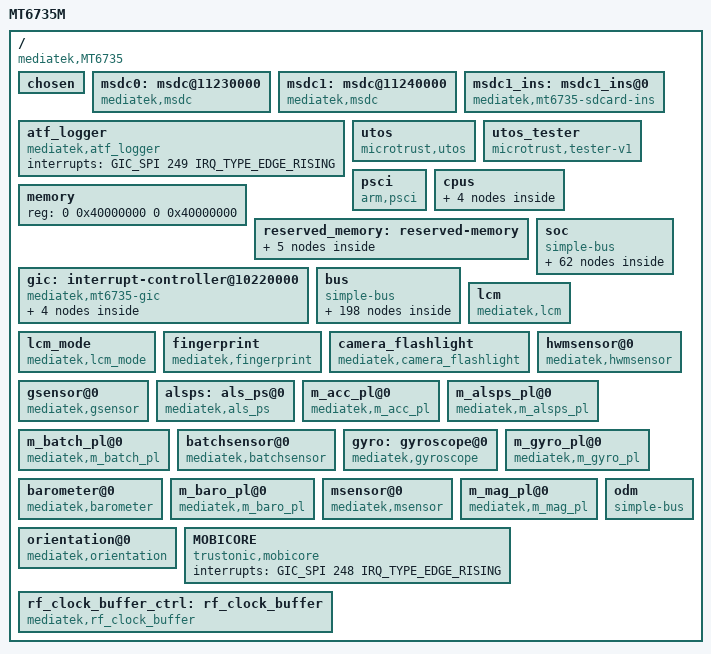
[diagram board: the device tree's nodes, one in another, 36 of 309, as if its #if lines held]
/*
 * Copyright (c) 2015 MediaTek Inc.
 *
 * This program is free software; you can redistribute it and/or modify
 * it under the terms of the GNU General Public License version 2 as
 * published by the Free Software Foundation.
 *
 * This program is distributed in the hope that it will be useful,
 * but WITHOUT ANY WARRANTY; without even the implied warranty of
 * MERCHANTABILITY or FITNESS FOR A PARTICULAR PURPOSE.  See the
 * GNU General Public License for more details.
 */

#include <dt-bindings/interrupt-controller/arm-gic.h>
#include <dt-bindings/interrupt-controller/irq.h>
#include "mt6735m-pinfunc.h"
#include <dt-bindings/mmc/mt6735-msdc.h>
#include <generated/autoconf.h>

#ifdef CONFIG_MTK_DTBO_FEATURE
/dts-v1/;
#endif

/ {
	model = "MT6735M";
	compatible = "mediatek,MT6735";
	interrupt-parent = <&gic>;
	#address-cells = <2>;
	#size-cells = <2>;

	/* chosen */
	chosen: chosen {
		bootargs = "console=tty0 console=ttyMT3,921600n1 vmalloc=400M \
androidboot.hardware=mt6735 slub_max_order=0 slub_debug=OFZPU swiotlb=noforce \
firmware_class.path=/vendor/firmware loop.max_part=7";
	};

	msdc0:msdc@11230000 {
		compatible = "mediatek,msdc";
		reg = <0 0x11230000 0 0x10000>;
		interrupts = <GIC_SPI 79 IRQ_TYPE_LEVEL_LOW>;
	};

	msdc1:msdc@11240000 {
		compatible = "mediatek,msdc";
		reg = <0 0x11240000 0 0x10000>;
		interrupts = <GIC_SPI 80 IRQ_TYPE_LEVEL_LOW>;
	};

	msdc1_ins:msdc1_ins@0 {
		compatible = "mediatek,mt6735-sdcard-ins";
	};

	/* ATF logger SW IRQ number 281 = 32 + 249 */
	atf_logger {
		compatible = "mediatek,atf_logger";
		interrupts = <GIC_SPI 249 IRQ_TYPE_EDGE_RISING>;
	};

	utos {
	compatible = "microtrust,utos";
	interrupts = <GIC_SPI 252 IRQ_TYPE_EDGE_RISING>,
		<GIC_SPI 253 IRQ_TYPE_EDGE_RISING>;
	};
	utos_tester {
		compatible = "microtrust,tester-v1";
	};

	psci {
		compatible	= "arm,psci";
		method		= "smc";
		cpu_suspend	= <0x84000001>;
		cpu_off		= <0x84000002>;
		cpu_on		= <0x84000003>;
		affinity_info	= <0x84000004>;
	};

	cpus: cpus {
		#address-cells = <1>;
		#size-cells = <0>;
/*		enable-method = "mediatek,mt6735-smp"; */

		cpu0: cpu@000 {
			device_type = "cpu";
			compatible = "arm,cortex-a53";
			reg = <0x000>;
			enable-method = "spin-table";
			cpu-release-addr = <0x0 0x40000200>;
			clock-frequency = <1000000000>;
		};

		cpu1: cpu@001 {
			device_type = "cpu";
			compatible = "arm,cortex-a53";
			reg = <0x001>;
			enable-method = "spin-table";
			cpu-release-addr = <0x0 0x40000200>;
			clock-frequency = <1000000000>;
		};

		cpu2: cpu@002 {
			device_type = "cpu";
			compatible = "arm,cortex-a53";
			reg = <0x002>;
			enable-method = "spin-table";
			cpu-release-addr = <0x0 0x40000200>;
			clock-frequency = <1000000000>;
		};

		cpu3: cpu@003 {
			device_type = "cpu";
			compatible = "arm,cortex-a53";
			reg = <0x003>;
			enable-method = "spin-table";
			cpu-release-addr = <0x0 0x40000200>;
			clock-frequency = <1000000000>;
		};
	};

	memory {
		device_type = "memory";
		reg = <0 0x40000000 0 0x40000000>;
	};


		reserved_memory: reserved-memory {
				#address-cells = <2>;
				#size-cells = <2>;
				ranges;

				/* reserve 192KB at DRAM start + 48MB */
				atf-reserved-memory@43000000 {
						compatible = "mediatek,mt6735-atf-reserved-memory",
						"mediatek,mt6735m-atf-reserved-memory",
						"mediatek,mt6753-atf-reserved-memory";
						no-map;
						reg = <0 0x43000000 0 0x30000>;
				};

		reserve-memory-ccci_md1 {
						compatible = "mediatek,reserve-memory-ccci_md1";
						no-map;
						size = <0 0x3810000>; // md_size+smem_size
						alignment = <0 0x2000000>;
						alloc-ranges = <0 0x40000000 0 0xC0000000>;
				};

				consys-reserve-memory {
						compatible = "mediatek,consys-reserve-memory";
						no-map;
						size = <0 0x100000>;
						alignment = <0 0x200000>;
				};

#ifdef CONFIG_MICROTRUST_TEE_SUPPORT
		soter-shared-mem {
			compatible = "microtrust,shared_mem";
			no-map;
			size = <0 0x200000>;
			alloc-ranges = <0 0x40000000 0 0x50000000>;
		};
#endif

				spm-reserve-memory {
					compatible = "mediatek,spm-reserve-memory";
					no-map;
					size = <0 0x10000>; /* PCM_FIRMWARE_SIZE * DYNA_LOAD_PCM_MAX = 4K * 4 */
					alignment = <0 0x10000>;
					alloc-ranges = <0 0x40000000 0 0x60000000>;
				};
		};

		gic: interrupt-controller@10220000 {
				compatible = "mediatek,mt6735-gic";
				#interrupt-cells = <3>;
				#address-cells = <0>;
				interrupt-controller;
				reg = <0 0x10221000 0 0x1000>,
					<0 0x10222000 0 0x1000>,
					<0 0x10200620 0 0x1000>;

				mediatek,wdt_irq = <160>;

				gic-cpuif@0 {
					compatible = "arm,gic-cpuif";
					cpuif-id = <0>;
					cpu = <&cpu0>;
				};

				gic-cpuif@1 {
					compatible = "arm,gic-cpuif";
					cpuif-id = <1>;
					cpu = <&cpu1>;
				};

				gic-cpuif@2 {
					compatible = "arm,gic-cpuif";
					cpuif-id = <2>;
					cpu = <&cpu2>;
				};

				gic-cpuif@3 {
					compatible = "arm,gic-cpuif";
					cpuif-id = <3>;
					cpu = <&cpu3>;
				};

		};

	soc {
		compatible = "simple-bus";
		#address-cells = <1>;
		#size-cells = <1>;
		ranges = <0 0 0 0xffffffff>;

		cpuxgpt: cpuxgpt@10200000 {
			compatible = "mediatek,mt6735-cpuxgpt";
			reg = <0x10200000 0x1000>;
			interrupts = <GIC_SPI 64 IRQ_TYPE_LEVEL_HIGH>,
				<GIC_SPI 65 IRQ_TYPE_LEVEL_HIGH>,
				<GIC_SPI 66 IRQ_TYPE_LEVEL_HIGH>,
				<GIC_SPI 67 IRQ_TYPE_LEVEL_HIGH>,
				<GIC_SPI 68 IRQ_TYPE_LEVEL_HIGH>,
				<GIC_SPI 69 IRQ_TYPE_LEVEL_HIGH>,
				<GIC_SPI 70 IRQ_TYPE_LEVEL_HIGH>,
				<GIC_SPI 71 IRQ_TYPE_LEVEL_HIGH>;
		};

		apxgpt: apxgpt@10004000 {
			compatible = "mediatek,APXGPT";
			reg = <0x10004000 0x1000>;
			interrupts = <GIC_SPI 152 IRQ_TYPE_LEVEL_LOW>;
			clock-frequency = <13000000>;
		};

		pmu {
			compatible = "arm,cortex-a7-pmu";
			interrupts = <GIC_SPI 8 IRQ_TYPE_LEVEL_LOW>,
				<GIC_SPI 9 IRQ_TYPE_LEVEL_LOW>,
				<GIC_SPI 10 IRQ_TYPE_LEVEL_LOW>,
				<GIC_SPI 11 IRQ_TYPE_LEVEL_LOW>;
			interrupt-affinity = <&cpu0>,
					     <&cpu1>,
					     <&cpu2>,
					     <&cpu3>;
		};

		timer {
			compatible = "arm,armv8-timer";
			interrupts = <GIC_PPI 13 IRQ_TYPE_LEVEL_LOW>, /*Secure Physical Timer Event*/
				<GIC_PPI 14 IRQ_TYPE_LEVEL_LOW>, /*Non-Secure Physical Timer Event*/
				<GIC_PPI 11 IRQ_TYPE_LEVEL_LOW>, /*Virtual Timer Event*/
				<GIC_PPI 10 IRQ_TYPE_LEVEL_LOW>; /*Hypervisor Timer Event*/
				clock-frequency = <13000000>;
		};

		mt_pmic_regulator {
			compatible = "mediatek,mt_pmic";
			/*reg = <0x01>*/
			buck_regulators {
			compatible = "mediatek,mt_pmic_buck_regulators";
				mt_pmic_vpa_buck_reg: buck_vpa {
					regulator-name = "vpa";
					regulator-min-microvolt = <500000>;
					regulator-max-microvolt = <3650000>;
					regulator-ramp-delay = <50000>;
					regulator-enable-ramp-delay = <180>;
				};
				mt_pmic_vproc_buck_reg: buck_vproc {
					regulator-name = "vproc";
					regulator-min-microvolt = <600000>;
					regulator-max-microvolt = <1393750>;
					regulator-ramp-delay = <6250>;
					regulator-enable-ramp-delay = <180>;
					regulator-always-on;
					regulator-boot-on;
				};
				mt_pmic_vcore1_buck_reg: buck_vcore1 {
					regulator-name = "vcore1";
					regulator-min-microvolt = <600000>;
					regulator-max-microvolt = <1393750>;
					regulator-ramp-delay = <6250>;
					regulator-enable-ramp-delay = <180>;
					regulator-always-on;
					regulator-boot-on;
				};
				mt_pmic_vsys22_buck_reg: buck_vsys22 {
					regulator-name = "vsys22";
					regulator-min-microvolt = <1200000>;
					regulator-max-microvolt = <1993750>;
					regulator-ramp-delay = <6250>;
					regulator-enable-ramp-delay = <180>;
					regulator-always-on;
					regulator-boot-on;
				};
				mt_pmic_vlte_buck_reg: buck_vlte {
					regulator-name = "vlte";
					regulator-min-microvolt = <600000>;
					regulator-max-microvolt = <1393750>;
					regulator-ramp-delay = <6250>;
					regulator-enable-ramp-delay = <180>;
					regulator-always-on;
					regulator-boot-on;
				};
			};	/* End of buck_regulators */
			ldo_regulators {
				compatible = "mediatek,mt_pmic_ldo_regulators";
				mt_pmic_vaux18_ldo_reg: ldo_vaux18 {
					regulator-name = "vaux18";
					regulator-min-microvolt = <1800000>;
					regulator-max-microvolt = <1800000>;
					regulator-enable-ramp-delay = <264>;
					regulator-boot-on;
				};
				mt_pmic_vtcxo_0_ldo_reg: ldo_vtcxo_0 {
					regulator-name = "vtcxo_0";
					regulator-min-microvolt = <2800000>;
					regulator-max-microvolt = <2800000>;
					regulator-enable-ramp-delay = <110>;
					regulator-boot-on;
				};
				mt_pmic_vtcxo_1_ldo_reg: ldo_vtcxo_1 {
					regulator-name = "vtcxo_1";
					regulator-min-microvolt = <2800000>;
					regulator-max-microvolt = <2800000>;
					regulator-enable-ramp-delay = <110>;
				};
				mt_pmic_vaud28_ldo_reg: ldo_vaud28 {
					regulator-name = "vaud28";
					regulator-min-microvolt = <2800000>;
					regulator-max-microvolt = <2800000>;
					regulator-enable-ramp-delay = <264>;
					regulator-boot-on;
				};
				mt_pmic_vcn28_ldo_reg: ldo_vcn28 {
					regulator-name = "vcn28";
					regulator-min-microvolt = <2800000>;
					regulator-max-microvolt = <2800000>;
					regulator-enable-ramp-delay = <264>;
				};
				mt_pmic_vcama_ldo_reg: ldo_vcama {
					regulator-name = "vcama";
					regulator-min-microvolt = <1500000>;
					regulator-max-microvolt = <2800000>;
					regulator-enable-ramp-delay = <264>;
				};
				mt_pmic_vcn33_bt_ldo_reg: ldo_vcn33_bt {
					regulator-name = "vcn33_bt";
					regulator-min-microvolt = <3300000>;
					regulator-max-microvolt = <3600000>;
					regulator-enable-ramp-delay = <264>;
				};
				mt_pmic_vcn33_wifi_ldo_reg: ldo_vcn33_wifi {
					regulator-name = "vcn33_wifi";
					regulator-min-microvolt = <3300000>;
					regulator-max-microvolt = <3600000>;
					regulator-enable-ramp-delay = <264>;
				};
				mt_pmic_vusb33_ldo_reg: ldo_vusb33 {
					regulator-name = "vusb33";
					regulator-min-microvolt = <3300000>;
					regulator-max-microvolt = <3300000>;
					regulator-enable-ramp-delay = <264>;
					regulator-boot-on;
				};
				mt_pmic_vefuse_ldo_reg: ldo_vefuse {
					regulator-name = "vefuse";
					regulator-min-microvolt = <1800000>;
					regulator-max-microvolt = <2200000>;
					regulator-enable-ramp-delay = <264>;
				};
				mt_pmic_vsim1_ldo_reg: ldo_vsim1 {
					regulator-name = "vsim1";
					regulator-min-microvolt = <1700000>;
					regulator-max-microvolt = <2100000>;
					regulator-enable-ramp-delay = <264>;
				};
				mt_pmic_vsim2_ldo_reg: ldo_vsim2 {
					regulator-name = "vsim2";
					regulator-min-microvolt = <1700000>;
					regulator-max-microvolt = <2100000>;
					regulator-enable-ramp-delay = <264>;
				};
				mt_pmic_vemc33_ldo_reg: ldo_vemc_3v3 {
					regulator-name = "vemc_3v3";
					regulator-min-microvolt = <1800000>;
					regulator-max-microvolt = <3300000>;
					regulator-enable-ramp-delay = <264>;
					regulator-boot-on;
				};
				mt_pmic_vmch_ldo_reg: ldo_vmch {
					regulator-name = "vmch";
					regulator-min-microvolt = <2900000>;
					regulator-max-microvolt = <3300000>;
					regulator-enable-ramp-delay = <44>;
				};
				mt_pmic_vtref_ldo_reg: ldo_vtref {
					regulator-name = "vtref";
					regulator-min-microvolt = <1800000>;
					regulator-max-microvolt = <1800000>;
					regulator-enable-ramp-delay = <240>;
				};
				mt_pmic_vmc_ldo_reg: ldo_vmc {
					regulator-name = "vmc";
					regulator-min-microvolt = <1800000>;
					regulator-max-microvolt = <3300000>;
					regulator-enable-ramp-delay = <44>;
				};
				mt_pmic_vcam_af_ldo_reg: ldo_vcamaf {
					regulator-name = "vcamaf";
					regulator-min-microvolt = <1200000>;
					regulator-max-microvolt = <3300000>;
					regulator-enable-ramp-delay = <264>;
				};
				mt_pmic_vio28_ldo_reg: ldo_vio28 {
					regulator-name = "vio28";
					regulator-min-microvolt = <2800000>;
					regulator-max-microvolt = <2800000>;
					regulator-enable-ramp-delay = <264>;
					regulator-boot-on;
				};
				mt_pmic_vgp1_ldo_reg: ldo_vgp1 {
					regulator-name = "vgp1";
					regulator-min-microvolt = <1200000>;
					regulator-max-microvolt = <3300000>;
					regulator-enable-ramp-delay = <264>;
				};
				mt_pmic_vibr_ldo_reg: ldo_vibr {
					regulator-name = "vibr";
					regulator-min-microvolt = <1200000>;
					regulator-max-microvolt = <3300000>;
					regulator-enable-ramp-delay = <44>;
				};
				mt_pmic_vcamd_ldo_reg: ldo_vcamd {
					regulator-name = "vcamd";
					regulator-min-microvolt = <900000>;
					regulator-max-microvolt = <1500000>;
					regulator-enable-ramp-delay = <264>;
				};
				mt_pmic_vrf18_0_ldo_reg: ldo_vrf18_0 {
					regulator-name = "vrf18_0";
					regulator-min-microvolt = <1825000>;
					regulator-max-microvolt = <1825000>;
					regulator-enable-ramp-delay = <220>;
				};
				mt_pmic_vrf18_1_ldo_reg: ldo_vrf18_1 {
					regulator-name = "vrf18_1";
					regulator-min-microvolt = <1200000>;
					regulator-max-microvolt = <1825000>;
					regulator-enable-ramp-delay = <220>;
				};
				mt_pmic_vio18_ldo_reg: ldo_vio18 {
					regulator-name = "vio18";
					regulator-min-microvolt = <1800000>;
					regulator-max-microvolt = <1800000>;
					regulator-enable-ramp-delay = <264>;
					regulator-boot-on;
				};
				mt_pmic_vcn18_ldo_reg: ldo_vcn18 {
					regulator-name = "vcn18";
					regulator-min-microvolt = <1800000>;
					regulator-max-microvolt = <1800000>;
					regulator-enable-ramp-delay = <44>;
				};
				mt_pmic_vcam_io_ldo_reg: ldo_vcamio {
					regulator-name = "vcamio";
					regulator-min-microvolt = <1200000>;
					regulator-max-microvolt = <1800000>;
					regulator-enable-ramp-delay = <220>;
				};
				mt_pmic_vsram_ldo_reg: ldo_vsram {
					regulator-name = "vsram";
					regulator-min-microvolt = <700000>;
					regulator-max-microvolt = <1493750>;
					regulator-enable-ramp-delay = <220>;
					regulator-ramp-delay = <6250>;
					regulator-boot-on;
				};
				mt_pmic_vm_ldo_reg: ldo_vm {
					regulator-name = "vm";
					regulator-min-microvolt = <1240000>;
					regulator-max-microvolt = <1540000>;
					regulator-enable-ramp-delay = <264>;
					regulator-boot-on;
				};
			};/* End of ldo_regulators */
			regulators_supply {
				compatible = "mediatek,mt_pmic_regulator_supply";
				vaux18-supply = <&mt_pmic_vaux18_ldo_reg>;
				vtcxo_0-supply = <&mt_pmic_vtcxo_0_ldo_reg>;
				vtcxo_1-supply = <&mt_pmic_vtcxo_1_ldo_reg>;
				vaud28-supply = <&mt_pmic_vaud28_ldo_reg>;
				vefuse-supply = <&mt_pmic_vefuse_ldo_reg>;
				vsim1-supply = <&mt_pmic_vsim1_ldo_reg>;
				vsim2-supply = <&mt_pmic_vsim2_ldo_reg>;
				vemc_3v3-supply = <&mt_pmic_vemc33_ldo_reg>;
				vmch-supply = <&mt_pmic_vmch_ldo_reg>;
				vtref-supply = <&mt_pmic_vtref_ldo_reg>;
				vmc-supply = <&mt_pmic_vmc_ldo_reg>;
				vio28-supply = <&mt_pmic_vio28_ldo_reg>;
				vibr-supply = <&mt_pmic_vibr_ldo_reg>;
				vrf18_0-supply = <&mt_pmic_vrf18_0_ldo_reg>;
				vrf18_1-supply = <&mt_pmic_vrf18_1_ldo_reg>;
				vio18-supply = <&mt_pmic_vio18_ldo_reg>;
				vsram-supply = <&mt_pmic_vsram_ldo_reg>;
				vm-supply = <&mt_pmic_vm_ldo_reg>;

			};/* End of regulators_supply */
		};/* End of mt_pmic_regulator */
		toprgu: toprgu@10212000 {
			compatible = "mediatek,mt6735-rgu";
			reg = <0x10212000 0x1000>;
			interrupts = <GIC_SPI 128 IRQ_TYPE_EDGE_FALLING>;
		};

		mcu_biu: mcu_biu@10300000 {
			compatible = "mediatek,mt6735-mcu_biu";
			reg = <0x10300000 0x8000>;
		};

		gpio_usage_mapping:gpio {
			compatible = "mediatek,gpio_usage_mapping";
		};

		gpio: gpio@10211000 {
			compatible = "mediatek,gpio";
			reg = <0x10211000 0x1000>;
		};

		dramc_nao: dramc_nao@1020e000 {
			compatible = "mediatek,mt6735-dramc_nao";
			reg = <0x1020e000 0x1000>;
		};

		ddrphy: ddrphy@10213000 {
			compatible = "mediatek,mt6735-ddrphy";
			reg = <0x10213000 0x1000>;
		};

		dramc: dramc@10214000 {
			compatible = "mediatek,mt6735-dramc";
			reg = <0x10214000 0x1000>;
			/*clocks = <&infrasys INFRA_GCE>;*/
			clock-names = "infra-cqdma";
		};

		apirtx:irtx@11011000 {
			compatible = "mediatek,irtx";
			reg = <0x11011000 0x1000>;
			interrupts = <GIC_SPI 124 IRQ_TYPE_LEVEL_HIGH>;
			pwm_ch = <0>;
		};

		apuart0: apuart0@11002000 {
			cell-index = <0>;
			compatible = "mediatek,mt6735-uart";
			skip_pinmux_clk = <1>;
			reg = <0x11002000 0x1000>, /* UART base */
				  <0x11000380 0x1000>, /* DMA Tx base */
				  <0x11000400 0x80>; /* DMA Rx base */
			interrupts = <GIC_SPI 91 IRQ_TYPE_LEVEL_LOW>, /* UART IRQ */
						 <GIC_SPI 103 IRQ_TYPE_LEVEL_LOW>, /* DMA Tx IRQ */
						 <GIC_SPI 104 IRQ_TYPE_LEVEL_LOW>; /* DMA Rx IRQ */
		};

		apuart1: apuart1@11003000 {
			cell-index = <1>;
			compatible = "mediatek,mt6735-uart";
			skip_pinmux_clk = <1>;
			reg = <0x11003000 0x1000>, /* UART base */
				  <0x11000480 0x80>, /* DMA Tx base */
				  <0x11000500 0x80>; /* DMA Rx base */
			interrupts = <GIC_SPI 92 IRQ_TYPE_LEVEL_LOW>, /* UART IRQ */
						 <GIC_SPI 105 IRQ_TYPE_LEVEL_LOW>, /* DMA Tx IRQ */
						 <GIC_SPI 106 IRQ_TYPE_LEVEL_LOW>; /* DMA Rx IRQ */
		};

		apuart2: apuart2@11004000 {
			cell-index = <2>;
			compatible = "mediatek,mt6735-uart";
			skip_pinmux_clk = <1>;
			reg = <0x11004000 0x1000>, /* UART base */
				  <0x11000580 0x80>, /* DMA Tx base */
				  <0x11000600 0x80>; /* DMA Rx base */
			interrupts = <GIC_SPI 93 IRQ_TYPE_LEVEL_LOW>, /* UART IRQ */
						 <GIC_SPI 107 IRQ_TYPE_LEVEL_LOW>, /* DMA Tx IRQ */
						 <GIC_SPI 108 IRQ_TYPE_LEVEL_LOW>; /* DMA Rx IRQ */
		};

		apuart3: apuart3@11005000 {
			cell-index = <3>;
			compatible = "mediatek,mt6735-uart";
			skip_pinmux_clk = <1>;
			reg = <0x11005000 0x1000>, /* UART base */
				  <0x11000680 0x80>, /* DMA Tx base */
				  <0x11000700 0x80>; /* DMA Rx base */
			interrupts = <GIC_SPI 94 IRQ_TYPE_LEVEL_LOW>, /* UART IRQ */
						 <GIC_SPI 109 IRQ_TYPE_LEVEL_LOW>, /* DMA Tx IRQ */
						 <GIC_SPI 110 IRQ_TYPE_LEVEL_LOW>; /* DMA Rx IRQ */
		};
		spi0:spi@1100a000 {
			compatible = "mediatek,mt6735m-spi";
			cell-index = <0>;
			spi-padmacro = <0>;
			reg = <0x1100a000 0x1000>;
			interrupts = <GIC_SPI 118 IRQ_TYPE_LEVEL_LOW>;
		};

		consys:consys@18070000 {
			compatible = "mediatek,mt6735m-consys",
						 "mediatek,mt6735-consys";
			reg = <0x18070000 0x0200>,  /*CONN_MCU_CONFIG_BASE      */
			      <0x10212000 0x0100>,  /*AP_RGU_BASE               */
			      <0x10000000 0x2000>,  /*TOPCKGEN_BASE             */
			      <0x10006000 0x1000>;  /*SPM_BASE                  */
			interrupts = <GIC_SPI 227 IRQ_TYPE_LEVEL_LOW>, /* BGF_EINT */
						 <GIC_SPI 225 IRQ_TYPE_LEVEL_LOW>; /* WDT_EINT */
			vcn18-supply = <&mt_pmic_vcn18_ldo_reg>;
			vcn28-supply = <&mt_pmic_vcn28_ldo_reg>;
			vcn33_bt-supply = <&mt_pmic_vcn33_bt_ldo_reg>;
			vcn33_wifi-supply = <&mt_pmic_vcn33_wifi_ldo_reg>;
		};

		hacc:hacc@10008000 {
			compatible = "mediatek,hacc";
			reg = <0x10008000 0x1000>;
			interrupts = <GIC_SPI 174 IRQ_TYPE_LEVEL_LOW>;
		};
		als: als {
			compatible = "mediatek, als-eint";
		};

		gse_1: gse_1 {
			compatible = "mediatek, gse_1-eint";
			status = "disabled";
		};
		ext_buck_oc: ext_buck_oc {
			compatible = "mediatek, ext_buck_oc-eint";
			status = "disabled";
		};
		swtp: swtp {
			compatible = "mediatek, swtp-eint";
		};

		dsi_te: dsi_te {
			compatible = "mediatek, DSI_TE_1-eint";
			status = "disabled";
		};

		hwrng: hwrng {
			compatible = "mediatek,mt67xx-rng";
		};
	};

	bus: bus {
		compatible = "simple-bus";
		#address-cells = <1>;
		#size-cells = <1>;
		ranges = <0 0 0 0xffffffff>;

		INFRACFG_AO@0x10000000 {
			compatible = "mediatek,INFRACFG_AO";
			reg = <0x10000000 0x1000>;
		};

		usb2jtag: usb2jtag@10000000 {
			compatible = "mediatek,usb2jtag_v1";
			reg = <0x10000000 0x1000>, <0x11210000 0x1000>;
		};

		PWRAP@0x10001000 {
			compatible = "mediatek,PWRAP";
			reg = <0x10001000 0x1000>;
			interrupts = <0 163 0x4>;
		};

		PERICFG@0x10002000 {
			compatible = "mediatek,PERICFG";
			reg = <0x10002000 0x1000>;
		};

		FHCTL@0x10209F00 {
			compatible = "mediatek,FHCTL";
			reg = <0x10209F00 0x100>;
		};

		keypad: keypad@10003000 {
			compatible = "mediatek,kp",
				"mediatek,mt6735-keypad",
				"mediatek,mt6735m-keypad";
			reg = <0x10003000 0x1000>;
			interrupts = <GIC_SPI 164 IRQ_TYPE_EDGE_FALLING>;
		};

		eintc: eintc@10005000 {
			compatible = "mediatek,mt-eic";
			reg = <0x10005000 0x1000>;
			interrupts = <GIC_SPI 153 IRQ_TYPE_LEVEL_HIGH>;

			#interrupt-cells = <2>;
			interrupt-controller;

			mediatek,max_eint_num = <213>;
			mediatek,mapping_table_entry = <0>;

			mediatek,debtime_setting_entry = <10>;
			mediatek,debtime_setting_array	= <0 125>,
							<1 250>,
							<2 500>,
							<3 1000>,
							<4 16000>,
							<5 32000>,
							<6 64000>,
							<7 128000>,
							<8 256000>,
							<9 512000>;
		};

				SLEEP@0x10006000 {
						compatible = "mediatek,SLEEP";
						reg = <0x10006000 0x1000>;
						interrupts = <0 165 0x8>,
												 <0 166 0x8>,
												 <0 167 0x8>,
												 <0 168 0x8>;
				};

		DEVAPC_AO@10007000 {
			compatible = "mediatek,DEVAPC_AO";
			reg = <0x10007000 0x1000>;
		};

		RSVD@0x10009000 {
			compatible = "mediatek,RSVD";
			reg = <0x10009000 0x1000>;
		};


		bat_meter {
			compatible = "mediatek,bat_meter";
			r_bat_sense = <0x4>;
			r_i_sense = <0x4>;
			r_charger_1 = <0x14a>;
			r_charger_2 = <0x27>;
			temperature_t0 = <0x6e>;
			temperature_t1 = <0x0>;
			temperature_t2 = <0x19>;
			temperature_t3 = <0x32>;
			temperature_t = <0xff>;
			fg_meter_resistance = <0x0>;
			q_max_pos_50 = <0xc92>;
			q_max_pos_25 = <0xc2d>;
			q_max_pos_0 = <0xace>;
			q_max_neg_10 = <0xc92>;
			q_max_pos_50_h_current = <0xc64>;
			q_max_pos_25_h_current = <0xbe5>;
			q_max_pos_0_h_current = <0x6c5>;
			q_max_neg_10_h_current = <0xc64>;
			oam_d5 = <0x1>;
			change_tracking_point = <0x1>;
			cust_tracking_point = <0x1>;
			cust_r_sense = <0x44>;
			cust_hw_cc = <0x0>;
			aging_tuning_value = <0x67>;
			cust_r_fg_offset = <0x0>;
			ocv_board_compesate = <0x0>;
			r_fg_board_base = <0x3e8>;
			r_fg_board_slope = <0x3e8>;
			car_tune_value = <0x5c>;
			current_detect_r_fg = <0xa>;
			minerroroffset = <0x3e8>;
			fg_vbat_average_size = <0x12>;
			r_fg_value = <0xa>;
			cust_poweron_delta_capacity_tolrance = <0x1e>;
			cust_poweron_low_capacity_tolrance = <0x5>;
			cust_poweron_max_vbat_tolrance = <0x5a>;
			cust_poweron_delta_vbat_tolrance = <0x1e>;
			cust_poweron_delta_hw_sw_ocv_capacity_tolrance = <0xa>;
			fixed_tbat_25 = <0x0>;
			vbat_normal_wakeup = <0xe10>;
			vbat_low_power_wakeup = <0xdac>;
			normal_wakeup_period = <0x1518>;
			low_power_wakeup_period = <0x12c>;
			close_poweroff_wakeup_period = <0x1e>;
			rbat_pull_up_r = <0x4204>;
			rbat_pull_up_volt = <0x708>;
			batt_temperature_table_num = <0x11>;
			batt_temperature_table = <0xffffffec 0x10a8d 0xfffffff1 0xd192 0xfffffff6 0xa60a 0xfffffffb 0x8464 0x0 0x6a53 0x5 0x5605 0xa 0x4606 0xf 0x3952 0x14 0x2f31 0x19 0x2710 0x1e 0x207b 0x23 0x1b24 0x28 0x16ca 0x2d 0x1335 0x32 0x1041 0x37 0xdcf 0x3c 0xbc6>;
			battery_profile_t0_num = <0x64>;
			battery_profile_t0 = <0x1 0x10f9 0x2 0x10f3 0x3 0x10e4 0x4 0x10d8 0x5 0x10d0 0x6 0x10c3 0x7 0x10b6 0x8 0x10af 0x9 0x109b 0xa 0x1094 0xb 0x108c 0xc 0x1078 0xd 0x106b 0xe 0x1064 0xf 0x105e 0x10 0x104a 0x11 0x1044 0x12 0x103d 0x13 0x102a 0x14 0x1024 0x15 0x101d 0x16 0x100b 0x17 0x1004 0x18 0xfff 0x19 0xfed 0x1a 0xfe6 0x1b 0xfe1 0x1c 0xfd1 0x1d 0xfcc 0x1e 0xfc4 0x1f 0xfb6 0x20 0xfb1 0x21 0xfaa 0x22 0xf9c 0x23 0xf97 0x24 0xf92 0x25 0xf81 0x26 0xf7d 0x27 0xf6f 0x28 0xf66 0x29 0xf4d 0x2a 0xf47 0x2b 0xf42 0x2c 0xf35 0x2d 0xf31 0x2e 0xf2d 0x2f 0xf22 0x30 0xf20 0x31 0xf1c 0x32 0xf12 0x33 0xf0e 0x34 0xf0c 0x35 0xf03 0x36 0xf01 0x37 0xefe 0x38 0xef5 0x39 0xef3 0x3a 0xef0 0x3b 0xee9 0x3c 0xee8 0x3d 0xee5 0x3e 0xee0 0x3f 0xedd 0x40 0xed9 0x41 0xed8 0x42 0xed3 0x43 0xed1 0x44 0xecf 0x45 0xec7 0x46 0xec4 0x47 0xebe 0x48 0xeb2 0x49 0xeb0 0x4a 0xead 0x4b 0xea7 0x4c 0xea5 0x4d 0xea1 0x4e 0xe9b 0x4f 0xe98 0x50 0xe97 0x51 0xe91 0x52 0xe8e 0x53 0xe8c 0x54 0xe81 0x55 0xe7d 0x56 0xe7b 0x56 0xe74 0x57 0xe6f 0x58 0xe6a 0x59 0xe67 0x5a 0xe64 0x5b 0xe64 0x5c 0xe62 0x5d 0xe61 0x5e 0xe59 0x5f 0xe53 0x60 0xe44 0x61 0xdfc 0x62 0xddc 0x64 0xdac>;
			battery_profile_t1_num = <0x64>;
			battery_profile_t1 = <0x0 0x10d9 0x1 0x10af 0x2 0x1083 0x3 0x1077 0x4 0x1066 0x5 0x105d 0x6 0x104e 0x7 0x1047 0x8 0x103e 0x9 0x1030 0xa 0x102a 0xb 0x1021 0xc 0x1014 0xd 0x100e 0xe 0x1001 0xf 0xffb 0x10 0xff6 0x11 0xfef 0x12 0xfe3 0x13 0xfdc 0x14 0xfcc 0x15 0xfc3 0x16 0xfb3 0x17 0xfac 0x18 0xfa0 0x19 0xf99 0x1a 0xf94 0x1b 0xf8b 0x1c 0xf86 0x1d 0xf81 0x1e 0xf76 0x1f 0xf86 0x20 0xf7a 0x21 0xf60 0x22 0xf59 0x23 0xf51 0x24 0xf43 0x25 0xf3a 0x26 0xf35 0x27 0xf30 0x28 0xf27 0x29 0xf22 0x2a 0xf1b 0x2b 0xf18 0x2c 0xf14 0x2d 0xf12 0x2e 0xf0a 0x2f 0xf04 0x30 0xf02 0x31 0xeff 0x32 0xef9 0x33 0xef7 0x34 0xef4 0x35 0xeef 0x37 0xeed 0x38 0xee8 0x39 0xee6 0x3a 0xee4 0x3b 0xee2 0x3c 0xedf 0x3d 0xedd 0x3e 0xedb 0x3f 0xeda 0x40 0xed9 0x41 0xed8 0x42 0xed6 0x43 0xed5 0x44 0xed3 0x45 0xed1 0x46 0xed0 0x47 0xecf 0x48 0xece 0x49 0xecb 0x4a 0xec9 0x4b 0xec7 0x4c 0xec6 0x4d 0xec3 0x4e 0xec0 0x4f 0xebe 0x50 0xeba 0x51 0xeb6 0x52 0xeb4 0x53 0xeaf 0x54 0xea8 0x55 0xea6 0x56 0xea2 0x57 0xe9c 0x58 0xe97 0x59 0xe90 0x5a 0xe8c 0x5b 0xe88 0x5c 0xe80 0x5d 0xe7b 0x5e 0xe78 0x5f 0xe73 0x60 0xe71 0x61 0xe6f 0x62 0xe6d 0x63 0xe6c 0x64 0xe69>;
			battery_profile_t2_num = <0x64>;
			battery_profile_t2 = <0x0 0x10f0 0x2 0x10d6 0x4 0x10be 0x6 0x10a6 0x8 0x108f 0xb 0x1078 0xd 0x1062 0xf 0x104b 0x11 0x1035 0x13 0x101f 0x15 0x100a 0x17 0xff5 0x19 0xfe4 0x1b 0xfcf 0x1e 0xfb9 0x20 0xfa5 0x22 0xf94 0x24 0xf84 0x26 0xf75 0x28 0xf5f 0x2a 0xf43 0x2c 0xf2f 0x2e 0xf21 0x31 0xf15 0x33 0xf0a 0x35 0xf00 0x37 0xef7 0x39 0xeee 0x3b 0xee7 0x3d 0xee0 0x3f 0xed9 0x41 0xed3 0x44 0xecd 0x46 0xec8 0x48 0xec1 0x4a 0xeb8 0x4c 0xeb0 0x4e 0xea8 0x50 0xea2 0x52 0xe9b 0x54 0xe90 0x56 0xe85 0x59 0xe78 0x5b 0xe6d 0x5d 0xe6b 0x5f 0xe68 0x61 0xe52 0x63 0xdf5 0x64 0xdac 0x64 0xdac 0x64 0xdac 0x64 0xdac 0x64 0xdac 0x64 0xdac 0x64 0xdac 0x64 0xdac 0x64 0xdac 0x64 0xdac 0x64 0xdac 0x64 0xdac 0x64 0xdac 0x64 0xdac 0x64 0xdac 0x64 0xdac 0x64 0xdac 0x64 0xdac 0x64 0xdac 0x64 0xdac 0x64 0xdac 0x64 0xdac 0x64 0xdac 0x64 0xdac 0x64 0xdac 0x64 0xdac 0x64 0xdac 0x64 0xdac 0x64 0xdac 0x64 0xdac 0x64 0xdac 0x64 0xdac 0x64 0xdac 0x64 0xdac 0x64 0xdac 0x64 0xdac 0x64 0xdac 0x64 0xdac 0x64 0xdac 0x64 0xdac 0x64 0xdac 0x64 0xdac 0x64 0xdac 0x64 0xdac 0x64 0xdac 0x64 0xdac 0x64 0xdac 0x64 0xdac 0x64 0xdac 0x64 0xdac 0x64 0xdac 0x64 0xdac>;
			battery_profile_t3_num = <0x64>;
			battery_profile_t3 = <0x0 0x10f9 0x1 0x10f3 0x2 0x10e4 0x3 0x10d8 0x4 0x10d0 0x5 0x10c3 0x6 0x10b6 0x7 0x10af 0x8 0x109b 0x9 0x1094 0xa 0x108c 0xb 0x1078 0xc 0x106b 0xd 0x1064 0xe 0x105e 0xf 0x104a 0x10 0x1044 0x11 0x103d 0x12 0x102a 0x13 0x1024 0x14 0x101d 0x15 0x100b 0x16 0x1004 0x17 0xfff 0x18 0xfed 0x19 0xfe6 0x1a 0xfe1 0x1b 0xfd1 0x1c 0xfcc 0x1d 0xfc4 0x1e 0xfb6 0x1f 0xfb1 0x20 0xfaa 0x21 0xf9c 0x22 0xf97 0x23 0xf92 0x24 0xf81 0x25 0xf7d 0x26 0xf6f 0x27 0xf66 0x28 0xf4d 0x29 0xf47 0x2a 0xf42 0x2b 0xf35 0x2c 0xf31 0x2d 0xf2d 0x2e 0xf22 0x2f 0xf20 0x30 0xf1c 0x31 0xf12 0x32 0xf0e 0x33 0xf0c 0x34 0xf03 0x35 0xf01 0x37 0xefe 0x38 0xef5 0x39 0xef3 0x3a 0xef0 0x3b 0xee9 0x3c 0xee8 0x3d 0xee5 0x3e 0xee0 0x3f 0xedd 0x40 0xed9 0x41 0xed8 0x42 0xed3 0x43 0xed1 0x44 0xecf 0x45 0xec7 0x46 0xec4 0x47 0xebe 0x48 0xeb2 0x49 0xeb0 0x4a 0xead 0x4b 0xea7 0x4c 0xea5 0x4d 0xea1 0x4e 0xe9b 0x4f 0xe98 0x50 0xe97 0x51 0xe91 0x52 0xe8e 0x53 0xe8c 0x54 0xe81 0x55 0xe7d 0x56 0xe7b 0x57 0xe74 0x58 0xe6f 0x59 0xe6a 0x5a 0xe67 0x5b 0xe64 0x5c 0xe64 0x5d 0xe62 0x5e 0xe61 0x5f 0xe59 0x60 0xe53 0x61 0xe44 0x62 0xdfc 0x63 0xddc 0x64 0xdac>;
			r_profile_t0_num = <0x64>;
			r_profile_t0 = <0x1a0 0x10d8 0x1a0 0x10bc 0x170 0x109d 0x151 0x1090 0x13e 0x1085 0x1e3 0x1076 0x1e9 0x106c 0x1c4 0x1061 0x205 0x1049 0x286 0x103d 0x1d1 0x1034 0x270 0x1028 0x1cd 0x1025 0x169 0x1015 0x214 0x1009 0x272 0x1000 0x1f6 0xffb 0x1b2 0xff6 0x182 0xfef 0x26a 0xfd0 0x1eb 0xfc4 0x1a6 0xfbc 0x176 0xfb4 0x193 0xfa3 0x216 0xf8a 0x1be 0xf85 0x189 0xf80 0x162 0xf7d 0x148 0xf78 0x120 0xf6f 0x112 0xf6b 0x108 0xf67 0xfe 0xf64 0x102 0xf5b 0x21f 0xf42 0x28d 0xf37 0x2eb 0xf2e 0x313 0xf2b 0x223 0xf27 0x19b 0xf21 0x16e 0xf1c 0x14d 0xf18 0x136 0xf14 0x123 0xf11 0x105 0xf09 0xfb 0xf05 0xf2 0xf03 0xe9 0xefe 0xe3 0xefa 0xe7 0xef3 0x1a6 0xeed 0x248 0xee8 0x1fe 0xee3 0x29b 0xedf 0x1e4 0xed8 0x1b2 0xed6 0x18e 0xed4 0x1d9 0xed1 0x1f0 0xece 0x1b8 0xecc 0x191 0xecc 0x208 0xec9 0x1b7 0xec9 0x20e 0xec4 0x1cd 0xec3 0x19e 0xec1 0x1e9 0xec0 0x323 0xebb 0x2a9 0xeb9 0x23b 0xeb7 0x1f5 0xeb6 0x1c4 0xeb5 0x182 0xeb1 0x16b 0xeb0 0x159 0xeaf 0x1d1 0xeac 0x266 0xea7 0x353 0xe9f 0x2d9 0xe9c 0x263 0xe9a 0x2af 0xe95 0x2df 0xe8c 0x290 0xe89 0x30b 0xe85 0x2d6 0xe81 0x27a 0xe80 0x317 0xe79 0x1e6 0xe76 0x2b7 0xe6f 0x34a 0xe69 0x2f7 0xe64 0x295 0xe5c 0x361 0xe4f 0x3e3 0xe43 0x3b4 0xe36 0x332 0xe2a 0x2ea 0xe1c 0x298 0xdee 0x363 0xdc3 0x418 0xdac>;
			r_profile_t1_num = <0x64>;
			r_profile_t1 = <0x302 0x10ed 0x302 0x10d8 0x350 0x10c8 0x36b 0x10ae 0x370 0x10a2 0x36e 0x1097 0x36e 0x108d 0x370 0x1083 0x36e 0x1070 0x36e 0x1066 0x36b 0x105c 0x36b 0x1053 0x369 0x1040 0x369 0x1038 0x36b 0x102f 0x364 0x1025 0x361 0x101d 0x369 0x100f 0x364 0x1007 0x366 0x1001 0x364 0xffa 0x369 0xff2 0x361 0xfe6 0x352 0xfcc 0x34a 0xfbf 0x346 0xfb3 0x346 0xfa8 0x33e 0xf95 0x343 0xf8e 0x33e 0xf86 0x341 0xf80 0x343 0xf7a 0x343 0xf74 0x343 0xf69 0x341 0xf62 0x33e 0xf5b 0x33e 0xf55 0x33c 0xf48 0x337 0xf41 0x337 0xf3b 0x339 0xf36 0x339 0xf30 0x339 0xf2b 0x339 0xf20 0x33e 0xf1b 0x33c 0xf16 0x33c 0xf12 0x33c 0xf08 0x341 0xf04 0x343 0xf01 0x346 0xefd 0x348 0xefa 0x350 0xef3 0x34d 0xeef 0x350 0xeeb 0x355 0xee9 0x357 0xee6 0x35f 0xee3 0x361 0xee0 0x361 0xede 0x369 0xedd 0x36e 0xedb 0x370 0xed9 0x375 0xed6 0x37d 0xed5 0x382 0xed3 0x382 0xed1 0x389 0xece 0x391 0xecc 0x396 0xecb 0x3a0 0xeca 0x3a2 0xec7 0x3ac 0xec6 0x3bb 0xec3 0x3c5 0xec0 0x3cf 0xebe 0x3d4 0xebb 0x3eb 0xeb5 0x3f0 0xeb1 0x40e 0xeab 0x41a 0xea7 0x43b 0xea0 0x44a 0xe9c 0x459 0xe96 0x46d 0xe91 0x47e 0xe8c 0x4b0 0xe82 0x4c9 0xe7d 0x4e5 0xe79 0x508 0xe76 0x523 0xe73 0x56e 0xe6d 0x599 0xe69 0x5c1 0xe63 0x5e9 0xe5a 0x616 0xe4e 0x659 0xe1b 0x681 0xdf5 0x6a7 0xdc1 0x6d6 0xdac>;
			r_profile_t2_num = <0x64>;
			r_profile_t2 = <0x9a 0x10f0 0x9a 0x10d6 0x9c 0x10be 0x9c 0x10a6 0x9d 0x108f 0x9d 0x1078 0xa0 0x1062 0xa0 0x104b 0xa1 0x1035 0xa3 0x101f 0xa6 0x100a 0xa6 0xff5 0xaa 0xfe4 0xb0 0xfcf 0xb1 0xfb9 0xb1 0xfa5 0xb4 0xf94 0xb3 0xf84 0xb4 0xf75 0xad 0xf5f 0x9c 0xf43 0x93 0xf2f 0x93 0xf21 0x92 0xf15 0x92 0xf0a 0x92 0xf00 0x93 0xef7 0x93 0xeee 0x96 0xee7 0x96 0xee0 0x96 0xed9 0x99 0xed3 0x9a 0xecd 0x9c 0xec8 0x99 0xec1 0x95 0xeb8 0x93 0xeb0 0x93 0xea8 0x96 0xea2 0x99 0xe9b 0x9a 0xe90 0x9d 0xe85 0xa0 0xe78 0xa1 0xe6d 0xa9 0xe6b 0xb4 0xe68 0xbf 0xe52 0xcc 0xdf5 0xf9 0xdac 0xf9 0xdac 0xf9 0xdac 0xf9 0xdac 0xf9 0xdac 0xf9 0xdac 0xf9 0xdac 0xf9 0xdac 0xf9 0xdac 0xf9 0xdac 0xf9 0xdac 0xf9 0xdac 0xf9 0xdac 0xf9 0xdac 0xf9 0xdac 0xf9 0xdac 0xf9 0xdac 0xf9 0xdac 0xf9 0xdac 0xf9 0xdac 0xf9 0xdac 0xf9 0xdac 0xf9 0xdac 0xf9 0xdac 0xf9 0xdac 0xf9 0xdac 0xf9 0xdac 0xf9 0xdac 0xf9 0xdac 0xf9 0xdac 0xf9 0xdac 0xf9 0xdac 0xf9 0xdac 0xf9 0xdac 0xf9 0xdac 0xf9 0xdac 0xf9 0xdac 0xf9 0xdac 0xf9 0xdac 0xf9 0xdac 0xf9 0xdac 0xf9 0xdac 0xf9 0xdac 0xf9 0xdac 0xf9 0xdac 0xf9 0xdac 0xf9 0xdac 0xf9 0xdac 0xf9 0xdac 0xf9 0xdac 0xf9 0xdac 0xf9 0xdac>;
			r_profile_t3_num = <0x64>;
			r_profile_t3 = <0x64 0x10f3 0x64 0x10e7 0x64 0x10db 0x62 0x10c6 0x64 0x10bc 0x67 0x10b3 0x67 0x10a9 0x67 0x1096 0x67 0x108c 0x69 0x1083 0x67 0x107a 0x67 0x1071 0x6c 0x1068 0x6c 0x1056 0x6e 0x104d 0x69 0x1043 0x69 0x103a 0x67 0x1028 0x69 0x1020 0x6e 0x1018 0x6e 0x100f 0x6e 0xffe 0x6c 0xff6 0x69 0xfec 0x69 0xfe5 0x6c 0xfdd 0x6c 0xfcd 0x70 0xfc7 0x6e 0xfbf 0x6e 0xfb6 0x71 0xfad 0x6e 0xf9f 0x71 0xf99 0x73 0xf93 0x6e 0xf8b 0x73 0xf85 0x76 0xf79 0x78 0xf73 0x76 0xf6c 0x73 0xf65 0x73 0xf5f 0x7b 0xf54 0x78 0xf4c 0x73 0xf42 0x6e 0xf38 0x67 0xf26 0x6c 0xf20 0x69 0xf19 0x69 0xf14 0x67 0xf0e 0x64 0xf0a 0x69 0xf02 0x69 0xefe 0x6c 0xefa 0x67 0xef5 0x67 0xeee 0x67 0xeea 0x69 0xee6 0x69 0xee4 0x6e 0xee2 0x69 0xeda 0x67 0xed6 0x69 0xed4 0x69 0xed1 0x69 0xecf 0x6c 0xeca 0x71 0xec9 0x71 0xec4 0x6e 0xec1 0x6e 0xebc 0x6e 0xeb9 0x69 0xeb5 0x69 0xeaf 0x69 0xea7 0x67 0xe9f 0x67 0xe9b 0x67 0xe98 0x6c 0xe95 0x69 0xe91 0x67 0xe8b 0x6c 0xe89 0x67 0xe85 0x67 0xe82 0x6e 0xe7b 0x6c 0xe76 0x69 0xe71 0x69 0xe6c 0x67 0xe67 0x69 0xe5a 0x69 0xe58 0x6c 0xe57 0x6e 0xe57 0x6c 0xe55 0x71 0xe53 0x73 0xe52 0x6c 0xe4b 0x6e 0xe40 0x71 0xe06 0x73 0xdde 0x73 0xdac>;
		};

		bat_notify {
			compatible = "mediatek,bat_notify";
		};

		bat_comm {
			compatible = "mediatek,battery";
			stop_charging_in_takling = <0x1>;
			talking_recharge_voltage = <0xed8>;
			talking_sync_time = <0x3c>;
			mtk_temperature_recharge_support = <0x1>;
			max_charge_temperature = <0x32>;
			max_charge_temperature_minus_x_degree = <0x2f>;
			min_charge_temperature = <0x0>;
			min_charge_temperature_plus_x_degree = <0x6>;
			err_charge_temperature = <0xff>;
			v_pre2cc_thres = <0xd48>;
			v_cc2topoff_thres = <0xfd2>;
			recharging_voltage = <0x100e>;
			charging_full_current = <0x64>;
			config_usb_if = <0x0>;
			usb_charger_current_suspend = <0x0>;
			usb_charger_current_unconfigured = <0x1b58>;
			usb_charger_current_configured = <0xc350>;
			usb_charger_current = <0xc350>;
			ac_charger_current = <0x186a0>;
			non_std_ac_charger_current = <0xc350>;
			charging_host_charger_current = <0xfde8>;
			apple_0_5a_charger_current = <0xc350>;
			apple_1_0a_charger_current = <0xfde8>;
			apple_2_1a_charger_current = <0x13880>;
			bat_low_temp_protect_enable = <0x0>;
			v_charger_enable = <0x0>;
			v_charger_max = <0x1964>;
			v_charger_min = <0x1130>;
			onehundred_percent_tracking_time = <0xa>;
			npercent_tracking_time = <0x14>;
			sync_to_real_tracking_time = <0x3c>;
			v_0percent_tracking = <0xdde>;
			high_battery_voltage_support = <0x1>;
		};

		mdcldma:mdcldma@1000A000 {
			compatible = "mediatek,mdcldma";
			reg =	<0x1000A000 0x1000>, /*AP_CLDMA_AO*/
				<0x1000B000 0x1000>, /*MD_CLDMA_AO*/
				<0x1021A000 0x1000>, /*AP_CLDMA_PDN*/
				<0x1021B000 0x1000>, /*MD_CLDMA_PDN*/
				<0x1020A000 0x1000>, /*AP_CCIF_BASE*/
				<0x1020B000 0x1000>; /*MD_CCIF_BASE*/
			interrupts =	<GIC_SPI 145 IRQ_TYPE_LEVEL_HIGH>, /*IRQ_CLDMA*/
					<GIC_SPI 140 IRQ_TYPE_LEVEL_LOW>, /*IRQ_CCIF*/
					<GIC_SPI 221 IRQ_TYPE_EDGE_FALLING>; /*IRQ_MDWDT*/
			mediatek,md_id = <0>;
			mediatek,cldma_capability = <2>;
			mediatek,md_smem_size = <0x10000>; /* md share memory size */
		};

		dbgapb_base@1011A000{
			compatible = "mediatek,dbgapb_base";
			reg = <0x1011A000 0x100>;/* MD debug register */
		};

		ssw:simswitch@0 {
			compatible = "mediatek,sim_switch";
			pinctrl-names =	"default",
					"hot_plug_mode1",
					"hot_plug_mode2",
					"two_sims_bound_to_md1",
					"sim1_md3_sim2_md1";
			pinctrl-0 = <&ssw_default>;
			pinctrl-1 = <&ssw_hot_plug_mode1>;
			pinctrl-2 = <&ssw_hot_plug_mode2>;
			pinctrl-3 = <&ssw_two_sims_bound_to_md1>;
			pinctrl-4 = <&ssw_sim1_md3_sim2_md1>;
		};

		DNL3_XGPT64@0x1000C000 {
			compatible = "mediatek,DNL3_XGPT64";
			reg = <0x1000C000 0x1000>;
			interrupts = <0 159 0x8>;
		};

		MCUCFG@0x10200000 {
			compatible = "mediatek,MCUCFG";
			reg = <0x10200000 0x200>;
			interrupts = <0 0 0x8>;
		};

		mcucfg: mcucfg@10200000 {
			compatible = "mediatek,mt6735-mcucfg";
			reg = <0x10200000 0x200>;
			interrupts = <GIC_SPI 71 IRQ_TYPE_LEVEL_HIGH>;
		};

		RSVD@0x10200200 {
			compatible = "mediatek,RSVD";
			reg = <0x10200200 0x200>;
		};

		MCUSYS_MISCCFG@0x10200400 {
			compatible = "mediatek,MCUSYS_MISCCFG";
			reg = <0x10200400 0x200>;
		};

		MCUSYS_MCUCFG@0x10200600 {
			compatible = "mediatek,MCUSYS_MCUCFG";
			reg = <0x10200600 0xa00>;
		};

		INFRACFG@0x10201000 {
			compatible = "mediatek,INFRACFG";
			reg = <0x10201000 0x1000>;
		};

		SRAMROM@0x10202000 {
			compatible = "mediatek,SRAMROM";
			reg = <0x10202000 0x1000>;
		};

		EMI@0x10203000 {
			compatible = "mediatek,EMI";
			reg = <0x10203000 0x1000>;
			interrupts = <0 136 0x4>;
		};

		sys_cirq: sys_cirq@10204000 {
			compatible = "mediatek,sys_cirq";
			reg = <0x10204000 0x1000>;
			interrupts = <GIC_SPI 231 IRQ_TYPE_LEVEL_LOW>;
			mediatek,cirq_num = <159>;
			mediatek,spi_start_offset = <72>;
		};

		m4u@10205000 {
			cell-index = <0>;
			compatible = "mediatek,m4u";
			reg = <0x10205000 0x1000>;
			interrupts = <GIC_SPI 146 IRQ_TYPE_LEVEL_LOW>;
		};

		EFUSEC@10206000 {
			compatible = "mediatek,EFUSEC";
			reg = <0x10206000 0x1000>;
		};

		DEVAPC@10207000 {
			compatible = "mediatek,DEVAPC";
			reg = <0x10207000 0x1000>;
			interrupts = <GIC_SPI 134 IRQ_TYPE_LEVEL_LOW>;
		};

		bus_dbg@10208000 {
			compatible = "mediatek,bus_dbg-v1";
			reg = <0x10208000 0x1000>;
			interrupts = <GIC_SPI 137 IRQ_TYPE_LEVEL_LOW>;
		};

		APMIXED@0x10209000 {
			compatible = "mediatek,APMIXED";
			reg = <0x10209000 0x1000>;
		};


		RSVD@0x1020C000 {
			compatible = "mediatek,RSVD";
			reg = <0x1020C000 0x1000>;
		};

		INFRA_MBIST@0x1020D000 {
			compatible = "mediatek,INFRA_MBIST";
			reg = <0x1020D000 0x1000>;
		};

		TRNG@0x1020F000 {
			compatible = "mediatek,TRNG";
			reg = <0x1020F000 0x1000>;
			interrupts = <0 141 0x8>;
		};

		CKSYS@0x10210000 {
			compatible = "mediatek,CKSYS";
			reg = <0x10210000 0x1000>;
		};

		MIPI_RX_ANA_CSI0@0x10215800 {
			compatible = "mediatek,MIPI_RX_ANA_CSI0";
			reg = <0x10215800 0x400>;
		};

		MIPI_RX_ANA_CSI1@0x10215C00 {
			compatible = "mediatek,MIPI_RX_ANA_CSI1";
			reg = <0x10215C00 0x400>;
		};

		gcpu@10216000 {
			compatible = "mediatek,gcpu";
			reg = <0x10216000 0x1000>;
			interrupts = <GIC_SPI 150 IRQ_TYPE_LEVEL_LOW>;
		};

		gce@10217000 {
			compatible = "mediatek,gce";
			reg = <0x10217000 0xc00>;
			interrupts = <GIC_SPI 151 IRQ_TYPE_LEVEL_LOW>,
						<GIC_SPI 148 IRQ_TYPE_LEVEL_LOW>;
			disp_mutex_reg = <0x14015000 0x1000>;
			g3d_config_base = <0x13000000 0 0xffff0000>;
			mmsys_config_base = <0x14000000 1 0xffff0000>;
			disp_dither_base = <0x14010000 2 0xffff0000>;
			mm_na_base = <0x14020000 3 0xffff0000>;
			imgsys_base = <0x15000000 4 0xffff0000>;
			vdec_gcon_base = <0x16000000 5 0xffff0000>;
			venc_gcon_base = <0x17000000 6 0xffff0000>;
			conn_peri_base = <0x18000000 7 0xffff0000>;
			topckgen_base = <0x10000000 8 0xffff0000>;
			kp_base = <0x10010000 9 0xffff0000>;
			scp_sram_base = <0x10020000 10 0xffff0000>;
			infra_na3_base = <0x10030000 11 0xffff0000>;
			infra_na4_base = <0x10040000 12 0xffff0000>;
			scp_base = <0x10050000 13 0xffff0000>;
			mcucfg_base = <0x10200000 14 0xffff0000>;
			gcpu_base = <0x10210000 15 0xffff0000>;
			usb0_base = <0x11200000 16 0xffff0000>;
			usb_sif_base = <0x11210000 17 0xffff0000>;
			audio_base = <0x11220000 18 0xffff0000>;
			msdc0_base = <0x11230000 19 0xffff0000>;
			msdc1_base = <0x11240000 20 0xffff0000>;
			msdc2_base = <0x11250000 21 0xffff0000>;
			msdc3_base = <0x11260000 22 0xffff0000>;
			pwm_sw_base = <0x1100E000 99 0xfffff000>;
			mdp_rdma0_sof = <0>;
			mdp_rsz0_sof = <1>;
			mdp_rsz1_sof = <2>;
			mdp_tdshp_sof = <3>;
			mdp_wdma_sof = <4>;
			mdp_wrot_sof = <5>;
			disp_ovl0_sof = <6>;
			disp_rdma0_sof = <8>;
			disp_rdma1_sof = <9>;
			disp_wdma0_sof = <10>;
			disp_ccorr_sof = <11>;
			disp_color_sof = <12>;
			disp_aal_sof = <13>;
			disp_gamma_sof = <14>;
			disp_dither_sof = <15>;
			disp_pwm0_sof = <17>;
			mdp_rdma0_frame_done = <18>;
			mdp_rsz0_frame_done = <19>;
			mdp_rsz1_frame_done = <20>;
			mdp_tdshp_frame_done = <21>;
			mdp_wdma_frame_done = <22>;
			mdp_wrot_write_frame_done = <23>;
			mdp_wrot_read_frame_done = <24>;
			disp_ovl0_frame_done = <25>;
			disp_rdma0_frame_done = <27>;
			disp_rdma1_frame_done = <28>;
			disp_wdma0_frame_done = <29>;
			disp_ccorr_frame_done = <30>;
			disp_color_frame_done = <31>;
			disp_aal_frame_done = <32>;
			disp_gamma_frame_done = <33>;
			disp_dither_frame_done = <34>;
			disp_dpi0_frame_done = <36>;
			disp_dsi0_frame_done = <37>;
			stream_done_0 = <38>;
			stream_done_1 = <39>;
			stream_done_2 = <40>;
			stream_done_3 = <41>;
			stream_done_4 = <42>;
			stream_done_5 = <43>;
			stream_done_6 = <44>;
			stream_done_7 = <45>;
			stream_done_8 = <46>;
			stream_done_9 = <47>;
			buf_underrun_event_0 = <48>;
			buf_underrun_event_1 = <49>;
			dsi0_te_event = <50>;
			isp_frame_done_p2_1 = <66>;
			isp_frame_done_p2_0 = <67>;
			seninf_cam0_fifo_full = <73>;
			apxgpt2_count = <0x10004028>;
		};

		smi_larb0@14016000 {
			cell-index = <0>;
			compatible = "mediatek,smi_larb0", "mediatek,smi_larb";
			reg = <0x14016000 0x1000>;
			interrupts = <GIC_SPI 176 IRQ_TYPE_LEVEL_LOW>;
		};

		smi_larb2@15001000 {
			cell-index = <2>;
			compatible = "mediatek,smi_larb2", "mediatek,smi_larb";
			reg = <0x15001000 0x1000>;
			interrupts = <GIC_SPI 178 IRQ_TYPE_LEVEL_LOW>;
		};

		smi_common@14017000 {
			compatible = "mediatek,smi_common";
			reg = <0x14017000 0x1000>,  /* SMI_COMMON_EXT */
				<0x14016000 0x1000>,  /* LARB 0 */
				<0x16010000 0x1000>,  /* LARB 1 */
				<0x15001000 0x1000>;  /* LARB 2 */
			nr_larbs = <3>;
			mmsys_config = <&mmsys_config>;
		};

		smi_larb1@16010000 {
			cell-index = <1>;
			compatible = "mediatek,smi_larb1", "mediatek,smi_larb";
			reg = <0x16010000 0x1000>;
			interrupts = <GIC_SPI 177 IRQ_TYPE_LEVEL_LOW>;
		};

		cqdma@10217c00 {
			compatible = "mediatek,cqdma";
			reg = <0x10217c00 0x400>;
			interrupts = <GIC_SPI 138 IRQ_TYPE_LEVEL_LOW>;
			nr_channel = <1>;
		};

		AP_CCIF1@0x10218000 {
			compatible = "mediatek,AP_CCIF1";
			reg = <0x10218000 0x1000>;
			interrupts = <0 139 0x4>;
		};

		MD_CCIF1@0x10219000 {
			compatible = "mediatek,MD_CCIF1";
			reg = <0x10219000 0x1000>;
		};

		INFRA_MD@0x1021C000 {
			compatible = "mediatek,INFRA_MD";
			reg = <0x1021C000 0x1000>;
		};

		DBGAPB@0x10400000 {
			compatible = "mediatek,DBGAPB";
			reg = <0x10400000 0xc00000>;
			interrupts = <0 132 0x8>;
		};

		DEBUGTOP_CA7L@0x10800000 {
			compatible = "mediatek,DEBUGTOP_CA7L";
			reg = <0x10800000 0x400000>;
		};

		DEBUGTOP_MD1@0x10450000 {
			compatible = "mediatek,DEBUGTOP_MD1";
			reg = <0x10450000 0x20000>;
		};

		DEBUGTOP_MD2@0x10470000 {
			compatible = "mediatek,DEBUGTOP_MD2";
			reg = <0x10470000 0x10000>;
		};

		CA9@0x10220000 {
			compatible = "mediatek,CA9";
			reg = <0x10220000 0x8000>;
		};

		cpu_dbgapb: cpu_dbgapb {
			compatible = "mediatek,hw_dbg";
			num = <4>;
			reg =  <0x10810000 0x1000
				0x10910000 0x1000
				0x10A10000 0x1000
				0x10B10000 0x1000>;
		};

		ap_dma:dma@11000000 {
			compatible = "mediatek,ap_dma";
			reg = <0x11000000 0x1000>;
			interrupts = <0 97 0x8>;
		};

		AP_DMA_IRDA@0x11000100 {
			compatible = "mediatek,AP_DMA_IRDA";
			reg = <0x11000100 0x80>;
			interrupts = <0 98 0x8>;
		};

		auxadc: adc_hw@11001000 {
			compatible = "mediatek,mt6735-auxadc";
			reg = <0x11001000 0x1000>;
			interrupts = <GIC_SPI 76 IRQ_TYPE_EDGE_FALLING>;
		};

		PWM@0x11006000 {
			compatible = "mediatek,pwm";
			reg = <0x11006000 0x1000>;
			interrupts = <0 77 0x8>;
		};
		syscfg_pctl_a: syscfg_pctl_a@0x10211000 {
			compatible = "mediatek,mt6735-pctl-a-syscfg", "syscon";
			reg = <0x10211000 0x1000>;
		};

		pio: pinctrl@0x10211000 {
			compatible = "mediatek,mt6735-pinctrl";
			reg = <0x10211000 0x1000>;
			mediatek,pctl-regmap = <&syscfg_pctl_a>;
			pins-are-numbered;
			gpio-controller;
			#gpio-cells = <2>;
		};

		i2c0:i2c@11007000 {
			compatible = "mediatek,mt6735m-i2c";
			cell-index = <0>;
			reg = <0x11007000 0x1000>;
			interrupts = <GIC_SPI 84 IRQ_TYPE_LEVEL_LOW>,
						<GIC_SPI 99 IRQ_TYPE_LEVEL_LOW>;
			def_speed = <100>;
		};

		i2c1:i2c@11008000 {
			compatible = "mediatek,mt6735m-i2c";
			cell-index = <1>;
			reg = <0x11008000 0x1000>;
			interrupts = <GIC_SPI 85 IRQ_TYPE_LEVEL_LOW>,
						<GIC_SPI 100 IRQ_TYPE_LEVEL_LOW>;
			def_speed = <100>;
		};

		i2c2:i2c@11009000 {
			compatible = "mediatek,mt6735m-i2c";
			cell-index = <2>;
			reg = <0x11009000 0x1000>;
			interrupts = <GIC_SPI 86 IRQ_TYPE_LEVEL_LOW>,
						<GIC_SPI 101 IRQ_TYPE_LEVEL_LOW>;
			def_speed = <100>;
		};

		i2c3:i2c@1100f000 {
			compatible = "mediatek,mt6735m-i2c";
			cell-index = <3>;
			reg = <0x1100f000 0x1000>;
			interrupts = <GIC_SPI 87 IRQ_TYPE_LEVEL_LOW>,
						<GIC_SPI 102 IRQ_TYPE_LEVEL_LOW>;
			def_speed = <100>;
		};

				G3D_CONFIG@0x13000000 {
						compatible = "mediatek,G3D_CONFIG";
						reg = <0x13000000 0x1000>;
				};


				IMGSYS@0x15000000 {
						compatible = "mediatek,IMGSYS";
						reg = <0x15000000 0x1000>;
				};

		SPI1@0x1100A000 {
			cell-index = <0>;
			spi-padmacro = <0>;
			compatible = "mediatek,SPI1";
			reg = <0x1100A000 0x1000>;
			interrupts = <0 118 0x8>;
		};

		touch: touch@ {
			compatible = "mediatek,touch";
			vtouch-supply = <&mt_pmic_vgp1_ldo_reg>;
		};

		accdet: accdet@ {
			compatible = "mediatek,pmic-accdet";
		};

		THERM_CTRL@0x1100B000 {
			compatible = "mediatek,THERM_CTRL";
			reg = <0x1100B000 0x1000>;
			interrupts = <0 78 0x8>;
		};

		ptp_fsm@1100b000 {
			compatible = "mediatek,ptp_fsm_v1";
			reg = <0x1100b000 0x1000>;
			interrupts = <GIC_SPI 125 IRQ_TYPE_LEVEL_LOW>;
		};

		btif@0x1100C000 {
			compatible = "mediatek,btif";
			#address-cells = <2>;
			#size-cells = <2>;
			reg = <0x1100C000 0x1000>,	/*btif base*/
				  <0x11000780 0x80>,	/*btif tx dma base*/
				  <0x11000800 0x80>;	/*btif rx dma base*/
			interrupts = <GIC_SPI 90 IRQ_TYPE_LEVEL_LOW>,	/*btif base*/
						 <GIC_SPI 111 IRQ_TYPE_LEVEL_LOW>,	/*btif tx dma base*/
						 <GIC_SPI 112 IRQ_TYPE_LEVEL_LOW>;	/*btif rx dma base*/
		};

		/* NFC start */
		nfc:nfc@0 {
			compatible = "mediatek,nfc-gpio-v2";
			gpio-ven = <4>;
			gpio-rst = <3>;
			gpio-eint = <1>;
			gpio-irq = <2>;
		};
		/* NFC end */

		gps {
			compatible = "mediatek,gps";
		};

		btcvsd@10000000 {
			compatible = "mediatek,audio_bt_cvsd";
			/*INFRA MISC, conn_bt_cvsd_mask, cvsd_mcu_read, write, packet_indicator*/
			offset = <0x700 0x800 0xfd0 0xfd4 0xfd8>;
			reg = <0x10000000 0x1000>, /*AUDIO_INFRA_BASE_PHYSICAL*/
				<0x18000000 0x10000>, /*PKV_PHYSICAL_BASE*/
				<0x18080000 0x8000>; /*SRAM_BANK2*/
			interrupts = <GIC_SPI 228 IRQ_TYPE_LEVEL_LOW>;
		};

		wifi@180F0000 {
			compatible = "mediatek,wifi";
			reg = <0x180F0000 0x005c>;
			interrupts = <GIC_SPI 226 IRQ_TYPE_LEVEL_LOW>;
		};

		NFI@0x1100D000 {
			compatible = "mediatek,NFI";
			reg = <0x1100D000 0x1000>;
			interrupts = <0 96 0x8>;
		};

		DISP_PWM0@0x1100E000 {
			compatible = "mediatek,DISP_PWM0";
			reg = <0x1100E000 0x1000>;
		};

		IRDA@0x11010000 {
			compatible = "mediatek,IRDA";
			reg = <0x11010000 0x1000>;
		};

		usb0:usb20@11200000 {
			compatible = "mediatek,mt6735-usb20";
			cell-index = <0>;
			reg = <0x11200000 0x10000>,
						<0x11210000 0x10000>;
			interrupts = <0 72 0x8>;
			mode = <2>;
			multipoint = <1>;
			dyn_fifo = <1>;
			soft_con = <1>;
			dma = <1>;
			num_eps = <16>;
			dma_channels = <8>;
			drvvbus_gpio = <83 2>;
		};

		usbiddig:usbiddig {
			compatible = "mediatek,usb_iddig_eint";
		};

		audio@11220000 {
			compatible = "mediatek,audio";
			reg = <0x11220000 0x10000>;
			interrupts = <GIC_SPI 144 IRQ_TYPE_LEVEL_LOW>;
		};

		audgpio: mt_soc_dl1_pcm@11220000 {
			compatible = "mediatek,mt-soc-dl1-pcm";
			reg = <0x11220000 0x1000>;
			interrupts = <GIC_SPI 144 IRQ_TYPE_LEVEL_LOW>;
			audclk-gpio = <143 0>;
			audmiso-gpio = <144 0>;
			audmosi-gpio = <145 0>;
			vowclk-gpio = <148 0>;
			extspkamp-gpio = <117 0>;
			i2s1clk-gpio = <80 0>;
			i2s1dat-gpio = <78 0>;
			i2s1mclk-gpio = <9 0>;
			i2s1ws-gpio = <79 0>;
		};

		mt_soc_ul1_pcm{
			compatible = "mediatek,mt_soc_pcm_capture";
		};

		mt_soc_voice_md1{
			compatible = "mediatek,mt_soc_pcm_voice_md1";
		};

		mt_soc_hdmi_pcm{
			compatible = "mediatek,mt_soc_pcm_hdmi";
		};

		mt_soc_uldlloopback_pcm{
			compatible = "mediatek,mt_soc_pcm_uldlloopback";
		};

		mt_soc_i2s0_pcm{
			compatible = "mediatek,mt_soc_pcm_dl1_i2s0";
		};

		mt_soc_mrgrx_pcm{
			compatible = "mediatek,mt_soc_pcm_mrgrx";
		};

		mt_soc_mrgrx_awb_pcm{
			compatible = "mediatek,mt_soc_pcm_mrgrx_awb";
		};

		mt_soc_fm_i2s_pcm{
			compatible = "mediatek,mt_soc_pcm_fm_i2s";
		};

		mt_soc_fm_i2s_awb_pcm{
			compatible = "mediatek,mt_soc_pcm_fm_i2s_awb";
		};

		mt_soc_i2s0dl1_pcm {
			compatible = "mediatek,mt_soc_pcm_dl1_i2s0Dl1";
		};

		mt_soc_deep_buffer_dl_pcm {
			compatible = "mediatek,mt_soc_pcm_deep_buffer_dl";
		};

		mt_soc_dl1_awb_pcm{
			compatible = "mediatek,mt_soc_pcm_dl1_awb";
		};

		mt_soc_voice_md1_bt{
			compatible = "mediatek,mt_soc_pcm_voice_md1_bt";
		};

		mt_soc_voip_bt_out {
			compatible = "mediatek,mt_soc_pcm_dl1_bt";
		};

		mt_soc_voip_bt_in {
			compatible = "mediatek,mt_soc_pcm_bt_dai";
		};

		mt_soc_tdmrx_pcm {
			compatible = "mediatek,mt_soc_tdm_capture";
		};

		mt_soc_fm_mrgtx_pcm {
			compatible = "mediatek,mt_soc_pcm_fmtx";
		};

		mt_soc_ul2_pcm {
			compatible = "mediatek,mt_soc_pcm_capture2";
		};

		mt_soc_i2s0_awb_pcm {
			compatible = "mediatek,mt_soc_pcm_i2s0_awb";
		};

		mt_soc_voice_md2 {
			compatible = "mediatek,mt_soc_pcm_voice_md2";
		};

		mt_soc_routing_pcm {
			compatible = "mediatek,mt_soc_pcm_routing";
			i2s1clk-gpio = <7 6>;
			i2s1dat-gpio = <5 6>;
			i2s1mclk-gpio = <9 6>;
			i2s1ws-gpio = <6 6>;
		};

		mt_soc_voice_md2_bt {
			compatible = "mediatek,mt_soc_pcm_voice_md2_bt";
		};

		mt_soc_hp_impedance_pcm {
			compatible = "mediatek,Mt_soc_pcm_hp_impedance";
		};

		mt_soc_codec_name {
			compatible = "mediatek,mt_soc_codec_63xx";
		};

		mt_soc_dummy_pcm {
			compatible = "mediatek,mt_soc_pcm_dummy";
		};

		mt_soc_codec_dummy_name {
			compatible = "mediatek,mt_soc_codec_dummy";
		};

		mt_soc_routing_dai_name {
			compatible = "mediatek,mt_soc_dai_routing";
		};

		mt_soc_dai_name {
			compatible = "mediatek,mt_soc_dai_stub";
		};

		mt_soc_offload_gdma {
			compatible = "mediatek,mt_soc_pcm_offload_gdma";
		};

		mt_soc_dl2_pcm {
			compatible = "mediatek,mt_soc_pcm_dl2";
		};

		USB1@0x11260000 {
			compatible = "mediatek,USB1";
			reg = <0x11260000 0x10000>;
			interrupts = <0 73 0x8>;
		};



		WCN_AHB@0x11270000 {
			compatible = "mediatek,WCN_AHB";
			reg = <0x11270000 0x10000>;
			interrupts = <0 228 0x8>;
		};

		MDPERIPHERALS@0x20000000 {
			compatible = "mediatek,MD PERIPHERALS";
			reg = <0x20000000 0x0>;
		};

		MD2PERIPHERALS@0x30000000 {
			compatible = "mediatek,MD2 PERIPHERALS";
			reg = <0x30000000 0x0>;
		};

		C2KPERIPHERALS@0x38000000 {
			compatible = "mediatek,C2K PERIPHERALS";
			reg = <0x38000000 0x0>;
		};

		MFGCFG@0x13000000 {
			compatible = "mediatek,MFGCFG";
			reg = <0x13000000 0x1000>;
			interrupts = <0 210 0x8>;
		};

		MALI@0x13040000 {
			compatible = "arm,malit720", "arm,mali-t72x", "arm,malit7xx", "arm,mali-midgard";
			reg = <0x13040000 0x4000>;
			interrupts = <0 212 0x8>, <0 211 0x8>, <0 210 0x8>;
			interrupt-names = "JOB", "MMU", "GPU";
			clock-frequency = <450000000>;
		};

		mmsys_config: mmsys_config@14000000 {
			compatible = "mediatek,mmsys_config";
			reg = <0x14000000 0x1000>;
			interrupts = <GIC_SPI 206 IRQ_TYPE_LEVEL_LOW>;
		};

		mdp_rdma@14001000 {
			compatible = "mediatek,mdp_rdma";
			reg = <0x14001000 0x1000>;
			interrupts = <GIC_SPI 187 IRQ_TYPE_LEVEL_LOW>;
		};

		mdp_rsz0@14002000 {
			compatible = "mediatek,mdp_rsz0";
			reg = <0x14002000 0x1000>;
			interrupts = <GIC_SPI 188 IRQ_TYPE_LEVEL_LOW>;
		};

		mdp_rsz1@14003000 {
			compatible = "mediatek,mdp_rsz1";
			reg = <0x14003000 0x1000>;
			interrupts = <GIC_SPI 189 IRQ_TYPE_LEVEL_LOW>;
		};

		mdp_wdma@14004000 {
			compatible = "mediatek,mdp_wdma";
			reg = <0x14004000 0x1000>;
			interrupts = <GIC_SPI 191 IRQ_TYPE_LEVEL_LOW>;
		};

		mdp_wrot@14005000 {
			compatible = "mediatek,mdp_wrot";
			reg = <0x14005000 0x1000>;
			interrupts = <GIC_SPI 192 IRQ_TYPE_LEVEL_LOW>;
		};

		mdp_tdshp@14006000 {
			compatible = "mediatek,mdp_tdshp";
			reg = <0x14006000 0x1000>;
			interrupts = <GIC_SPI 190 IRQ_TYPE_LEVEL_LOW>;
		};

		DISPSYS@14007000 {
			compatible = "mediatek,DISPSYS";
			reg = <0x14007000 0x1000>,  /*DISP_OVL0      */
				<0 0>,  /*DISP_OVL1     */
				<0x14009000 0x1000>,  /*DISP_RDMA0     */
				<0 0>,  /*DISP_RDMA1     */
				<0x1400b000 0x1000>,  /*DISP_WDMA0     */
				<0x1400c000 0x1000>,  /*DISP_COLOR     */
				<0x1400d000 0x1000>,  /*DISP_CCORR     */
				<0x1400e000 0x1000>,  /*DISP_AAL       */
				<0x1400f000 0x1000>,  /*DISP_GAMMA     */
				<0x14010000 0x1000>,  /*DISP_DITHER    */
				<0 0>,  /*DISP_UFOE      */
				<0x1100e000 0x1000>,  /*DISP_PWM       */
				<0 0>,  /*DISP_WDMA1     */
				<0x14015000 0x1000>,  /*DISP_MUTEX     */
				<0x14012000 0x1000>,  /*DISP_DSI0      */
				<0x14013000 0x1000>,  /*DISP_DPI0      */
				<0x14000000 0x1000>,  /*DISP_CONFIG    */
				<0x14016000 0x1000>,  /*DISP_SMI_LARB0 */
				<0x14017000 0x1000>,  /*DISP_SMI_COMMOM*/
				<0x14018000 0x1000>,      /*MIPITX0,real chip would use this:<0x14017000 0x1000>;*/
				<0x10206000 0x1000>,  /*DISP_CONFIG2*/
				<0x10210000 0x1000>,  /*DISP_CONFIG3*/
				<0x10211a70 0x000C>,  /*DISP_DPI_IO_DRIVING1 */
				<0x10211974 0x000C>,  /*DISP_DPI_IO_DRIVING2 */
				<0x10211b70 0x000C>,  /*DISP_DPI_IO_DRIVING3 */
				<0x10206044 0x000C>,  /*DISP_DPI_USE */
				<0x10206514 0x000C>,  /*DISP_DPI_USE_PERMISSION */
				<0x10206558 0x000C>,  /*DISP_DPI_USE_KEY */
				<0x102100a0 0x1000>,  /*DISP_TVDPLL_CFG6 */
				<0x10209260 0x1000>,  /*DISP_TVDPLL_CON0 */
				<0x10209264 0x1000>,  /*DISP_TVDPLL_CON1 */
				<0 0>,  /*DISP_OD      */
				<0x10209000 0x1000>;  /*DISP_VENCPLL      */

			interrupts = <0 193 8>, /*DISP_OVL0 */
				 <0 0 8>, /*DISP_OVL1 */
				 <0 195 8>, /*DISP_RDMA0 */
				 <0 0 8>, /*DISP_RDMA1 */
				 <0 197 8>, /*DISP_WDMA0 */
				 <0 198 8>, /*DISP_COLOR */
				 <0 199 8>, /*DISP_CCORR */
				 <0 200 8>, /*DISP_AAL */
				 <0 201 8>, /*DISP_GAMMA */
				 <0 202 8>, /*DISP_DITHER */
				 <0 0 8>, /*DISP_UFOE */
				 <0 117 8>, /*DISP_PWM */
				 <0 0 8>, /*DISP_WDMA1 */
				 <0 186 8>, /*DISP_MUTEX */
				 <0 204 8>, /*DISP_DSI0 */
				 <0 205 8>, /*DISP_DPI0 */
				 <0 206 8>, /*DISP_CONFIG, 0 means no IRQ*/
				 <0 176 8>, /*DISP_SMI_LARB0 */
				 <0 0 8>, /*DISP_SMI_COMMOM*/
				 <0 0 8>,      /*MIPITX0,real chip would use this:<0x14017000 0x1000>;*/
				 <0 0 8>,  /*DISP_CONFIG2*/
				 <0 0 8>,  /*DISP_CONFIG3*/
				 <0 0 8>,  /*DISP_DPI_IO_DRIVING */
				 <0 0 8>,  /*DISP_TVDPLL_CFG6 */
				 <0 0 8>,  /*DISP_TVDPLL_CON0 */
				 <0 0 8>,  /*DISP_TVDPLL_CON1 */
				 <0 0 8>,  /*DISP_OD      */
				 <0 0 8>;  /*DISP_VENCPLL      */
				};

		DISP_OVL0@0x14007000 {
			compatible = "mediatek,DISP_OVL0";
			reg = <0x14007000 0x1000>;
			interrupts = <0 193 0x8>;
		};

		DISP_OVL1@0x14008000 {
			compatible = "mediatek,DISP_OVL1";
			reg = <0x14008000 0x1000>;
			interrupts = <0 194 0x8>;
		};

		DISP_RDMA0@0x14009000 {
			compatible = "mediatek,DISP_RDMA0";
			reg = <0x14009000 0x1000>;
			interrupts = <0 195 0x8>;
		};

		DISP_RDMA1@0x1400A000 {
			compatible = "mediatek,DISP_RDMA1";
			reg = <0x1400A000 0x1000>;
			interrupts = <0 196 0x8>;
		};

		gpio@0x10000e00 {
			compatible = "mediatek,fpga_gpio";
			reg = <0x10000e00 0x100>;
		};

		DISP_WDMA0@0x1400B000 {
			compatible = "mediatek,DISP_WDMA0";
			reg = <0x1400B000 0x1000>;
			interrupts = <0 197 0x8>;
		};

		DISP_COLOR@0x1400C000 {
			compatible = "mediatek,DISP_COLOR";
			reg = <0x1400C000 0x1000>;
			interrupts = <0 198 0x8>;
		};

		DISP_CCORR@0x1400D000 {
			compatible = "mediatek,DISP_CCORR";
			reg = <0x1400D000 0x1000>;
			interrupts = <0 199 0x8>;
		};

		DISP_AAL@0x1400E000 {
			compatible = "mediatek,DISP_AAL";
			reg = <0x1400E000 0x1000>;
			interrupts = <0 200 0x8>;
		};

		DISP_GAMMA@0x1400F000 {
			compatible = "mediatek,DISP_GAMMA";
			reg = <0x1400F000 0x1000>;
			interrupts = <0 201 0x8>;
		};

		DISP_DITHER@0x14010000 {
			compatible = "mediatek,DISP_DITHER";
			reg = <0x14010000 0x1000>;
			interrupts = <0 202 0x8>;
		};

		DISP_UFOE@0x14011000 {
			compatible = "mediatek,DISP_UFOE";
			reg = <0x14011000 0x1000>;
			interrupts = <0 203 0x8>;
		};

		DSI0@0x14012000 {
			compatible = "mediatek,DSI0";
			reg = <0x14012000 0x1000>;
			interrupts = <0 204 0x8>;
		};

		DPI0@0x14013000 {
			compatible = "mediatek,DPI0";
			reg = <0x14013000 0x1000>;
			interrupts = <0 205 0x8>;
		};

		DISP_PWM@0x14014000 {
			compatible = "mediatek,DISP_PWM";
			reg = <0x14014000 0x1000>;
		};

		MM_MUTEX@0x14015000 {
			compatible = "mediatek,MM_MUTEX";
			reg = <0x14015000 0x1000>;
			interrupts = <0 186 0x8>;
		};

		met_smi: met_smi@14017000 {
			compatible = "mediatek,met_smi";
			reg = <0x14017000 0x1000>,  /* SMI_COMMON_EXT */
					<0x14016000 0x1000>,  /* LARB 0 */
					<0x16010000 0x1000>,  /* LARB 1 */
					<0x15001000 0x1000>,  /* LARB 2 */
					<0x17001000 0x1000>;  /* LARB 3 */
			/*
			clocks = <&mmsys MM_DISP0_SMI_COMMON>,
						 <&mmsys MM_DISP0_SMI_LARB0>,
						 <&imgsys IMG_IMAGE_LARB2_SMI>,
						 <&vdecsys VDEC0_VDEC>,
						 <&vdecsys VDEC1_LARB>,
						 <&vencsys VENC_LARB>,
						 <&vencsys VENC_VENC>;

			clock-names = "smi-common",
				"smi-larb0",
				"img-larb2",
				"vdec0-vdec",
				"vdec1-larb",
				"venc-larb",
				"venc-venc";
			*/
		};


		MIPI_TX_CONFIG@0x14018000 {
			compatible = "mediatek,MIPI_TX_CONFIG";
			reg = <0x14018000 0x1000>;
		};

								ISPSYS@0x15000000 {
			compatible = "mediatek,ISPSYS";
			reg = <0x15004000 0x9000>,  /*ISP_ADDR      */
				<0x15000000 0x10000>,  /*IMGSYS_CONFIG_ADDR      */
				<0x10215000 0x1000>;  /*MIPI_ANA_ADDR      */
			interrupts = <0 182 0x8>, /* SENINF */
									 <0 183 0x8>; /* CAM0 */
		};
		kd_camera_hw1:kd_camera_hw1@15008000 {
			compatible = "mediatek,camera_hw";
			reg = <0x15008000 0x1000>;  /* SENINF_ADDR */
			vcama-supply = <&mt_pmic_vcama_ldo_reg>;
			vcamd-supply = <&mt_pmic_vcamd_ldo_reg>;
			vcamaf-supply = <&mt_pmic_vcam_af_ldo_reg>;
			vcamio-supply = <&mt_pmic_vcam_io_ldo_reg>;
		};
		kd_camera_hw2:kd_camera_hw2@15008000 {
			compatible = "mediatek,camera_hw2";
			reg = <0x15008000 0x1000>;  /* SENINF_ADDR */
		};
								/*for sysram dev and pipemgr dev*/
								ISP_SYSR@0x15000000 {
			compatible = "mediatek,ISP_SYSR";
		};
								ISP_PIPEM@0x15000000 {
			compatible = "mediatek,ISP_PIPEM";
		};

		SENINF_TOP@0x15008000 {
			compatible = "mediatek,SENINF_TOP";
			reg = <0x15008000 0x1000>;
			interrupts = <0 182 0x8>;
		};

		CAM@0x15004000 {
			compatible = "mediatek,CAM";
			reg = <0x15004000 0x1000>;
			interrupts = <0 183 0x8>;
		};

		VENC@0x15009000 {
			compatible = "mediatek,VENC";
			reg = <0x15009000 0x1000>;
			interrupts = <0 180 0x8>;
		};

		VDEC@0x1500B000 {
			compatible = "mediatek,VDEC";
			reg = <0x1500B000 0x1000>;
		};

		JPGENC@0x1500A000 {
			compatible = "mediatek,JPGENC";
			reg = <0x1500A000 0x1000>;
			interrupts = <0 181 0x8>;
		};


		VDEC_GCON@0x16000000 {
			compatible = "mediatek,VDEC_GCON";
			reg = <0x16000000 0x1000>;
		};

		VDEC_FULL_TOP@0x16020000 {
			compatible = "mediatek,VDEC_FULL_TOP";
			reg = <0x16020000 0x10000>;
			interrupts = <0 179 0x8>;
		};

		CHIPID@08000000 {
			compatible = "mediatek,CHIPID";
			reg = <0x08000000 0x0004>,
									<0x08000004 0x0004>,
									<0x08000008 0x0004>,
									<0x0800000C 0x0004>;
		};
		pwm:pwm@11006000 {
			compatible = "mediatek,pwm";
			reg = <0x11006000 0x1000>;
			interrupts = <GIC_SPI 77 IRQ_TYPE_LEVEL_LOW>;
		};
	};
	lcm: lcm {
		compatible = "mediatek,lcm";
	};
	
       lcm_mode: lcm_mode {
		compatible = "mediatek,lcm_mode";
	};

  	fingerprint: fingerprint {
 		compatible = "mediatek,fingerprint";
 	};
 	camera_flashlight: camera_flashlight {
			compatible = "mediatek,camera_flashlight";
	};

/* sensor part */
		hwmsensor@0 {
			compatible = "mediatek,hwmsensor";
		};
		gsensor@0 {
			compatible = "mediatek,gsensor";
		};
		alsps:als_ps@0 {
			compatible = "mediatek,als_ps";
		};
		m_acc_pl@0 {
			compatible = "mediatek,m_acc_pl";
		};

		m_alsps_pl@0 {
			compatible = "mediatek,m_alsps_pl";
		};

		m_batch_pl@0 {
			compatible = "mediatek,m_batch_pl";
		};
		batchsensor@0 {
			compatible = "mediatek,batchsensor";
		};
		gyro:gyroscope@0 {
			compatible = "mediatek,gyroscope";
		};
		m_gyro_pl@0 {
			compatible = "mediatek,m_gyro_pl";
		};
		barometer@0 {
			compatible = "mediatek,barometer";
		};
		m_baro_pl@0 {
			compatible = "mediatek,m_baro_pl";
		};
		msensor@0 {
			compatible = "mediatek,msensor";
		};
		m_mag_pl@0 {
			compatible = "mediatek,m_mag_pl";
		};
		orientation@0 {
			compatible = "mediatek,orientation";
	};

/* sensor end */
	MOBICORE {
		compatible = "trustonic,mobicore";
		interrupts = <GIC_SPI 248 IRQ_TYPE_EDGE_RISING>;
	};

	rf_clock_buffer_ctrl:rf_clock_buffer {
		compatible = "mediatek,rf_clock_buffer";
		mediatek,clkbuf-quantity = <4>;
		mediatek,clkbuf-config = <2 1 1 1>;
	};

	odm: odm{
		compatible = "simple-bus";
		/* reserved for overlay by odm */
	};
};

&eintc {
	pmic@206 {
	compatible = "mediatek, pmic-eint";
	interrupt-parent = <&eintc>;
	interrupts = <206 4>;
	debounce = <206 1000>;
	};
};

&pio {
	ssw_default:ssw0default {
	};

	ssw_hot_plug_mode1:ssw@1 {

		pins_cmd0_dat {
			pinmux = <PINMUX_GPIO8__FUNC_MD_EINT1>;
		};

		pins_cmd1_dat {
			pinmux = <PINMUX_GPIO9__FUNC_MD_EINT2>;
		};
	};

	ssw_hot_plug_mode2:ssw@2 {

		pins_cmd0_dat {
			pinmux = <PINMUX_GPIO8__FUNC_C2K_UIM0_HOT_PLUG_IN>;
		};

		pins_cmd1_dat {
			pinmux = <PINMUX_GPIO9__FUNC_MD_EINT2>;
		};
	};

	ssw_two_sims_bound_to_md1:ssw@3 {
		pins_cmd0_dat {
			pinmux = <PINMUX_GPIO163__FUNC_MD_SIM1_SCLK>;
			slew-rate = <1>;
		};

		pins_cmd1_dat {
			pinmux = <PINMUX_GPIO164__FUNC_MD_SIM1_SRST>;
			slew-rate = <1>;
		};

		pins_cmd2_dat {
			pinmux = <PINMUX_GPIO165__FUNC_MD_SIM1_SDAT>;
			slew-rate = <0>;
			bias-pull-up = <00>;

		};

		pins_cmd3_dat {
			pinmux = <PINMUX_GPIO160__FUNC_MD_SIM2_SCLK>;
			slew-rate = <1>;
		};

		pins_cmd4_dat {
			pinmux = <PINMUX_GPIO161__FUNC_MD_SIM2_SRST>;
			slew-rate = <1>;
		};

		pins_cmd5_dat {
			pinmux = <PINMUX_GPIO162__FUNC_MD_SIM2_SDAT>;
			slew-rate = <0>;
			bias-pull-up = <00>;
		};
	};

	ssw_sim1_md3_sim2_md1:ssw@4 {
		pins_cmd0_dat {
			pinmux = <PINMUX_GPIO163__FUNC_UIM0_CLK>;
		};

		pins_cmd1_dat {
			pinmux = <PINMUX_GPIO164__FUNC_UIM0_RST>;
		};

		pins_cmd2_dat {
			pinmux = <PINMUX_GPIO165__FUNC_UIM0_IO>;
		};

		pins_cmd3_dat {
			pinmux = <PINMUX_GPIO160__FUNC_MD_SIM2_SCLK>;
		};

		pins_cmd4_dat {
			pinmux = <PINMUX_GPIO161__FUNC_MD_SIM2_SRST>;
		};

		pins_cmd5_dat {
			pinmux = <PINMUX_GPIO162__FUNC_MD_SIM2_SDAT>;
		};
	};
};
/*SSW end*/

/*GPIO standardization CLDMA*/
&mdcldma {
	pinctrl-names = "default", "vsram_output_low", "vsram_output_high", "RFIC0_01_mode", "RFIC0_04_mode";

	pinctrl-0 = <&vsram_default>;
	pinctrl-1 = <&vsram_output_low>;
	pinctrl-2 = <&vsram_output_high>;
	pinctrl-3 = <&RFIC0_01_mode>;
	pinctrl-4 = <&RFIC0_04_mode>;
};

&pio {
	vsram_default: vsram0default {
	};

	vsram_output_low: vsram@1 {
		pins_cmd_dat {
			pinmux = <PINMUX_GPIO140__FUNC_GPIO140>;
			slew-rate = <1>;
			output-low;
		};
	};

	vsram_output_high: vsram@2 {
		pins_cmd_dat {
			pinmux = <PINMUX_GPIO140__FUNC_GPIO140>;
			slew-rate = <1>;
			output-high;
		};
	};

	RFIC0_01_mode: clockbuf@1{

		pins_cmd0_dat {
			pinmux = <PINMUX_GPIO110__FUNC_RFIC0_BSI_EN>;
		};

		pins_cmd1_dat {
			pinmux = <PINMUX_GPIO111__FUNC_RFIC0_BSI_CK>;
		};

		pins_cmd2_dat {
			pinmux = <PINMUX_GPIO112__FUNC_RFIC0_BSI_D2>;
		};


		pins_cmd3_dat {
			pinmux = <PINMUX_GPIO113__FUNC_RFIC0_BSI_D1>;
		};

		pins_cmd4_dat {
			pinmux = <PINMUX_GPIO114__FUNC_RFIC0_BSI_D0>;
		};
	};

	RFIC0_04_mode: clockbuf@2{

		pins_cmd0_dat {
			pinmux = <PINMUX_GPIO110__FUNC_SPM_BSI_EN>;
		};

		pins_cmd1_dat {
			pinmux = <PINMUX_GPIO111__FUNC_SPM_BSI_CLK>;
		};

		pins_cmd2_dat {
			pinmux = <PINMUX_GPIO112__FUNC_SPM_BSI_D2>;
		};

		pins_cmd3_dat {
			pinmux = <PINMUX_GPIO113__FUNC_SPM_BSI_D1>;
		};

		pins_cmd4_dat {
			pinmux = <PINMUX_GPIO114__FUNC_SPM_BSI_D0>;
		};

	};
};


#include "cust_mt6735_msdc.dtsi"
/*CLDMA end*/

#include <trusty.dtsi>
